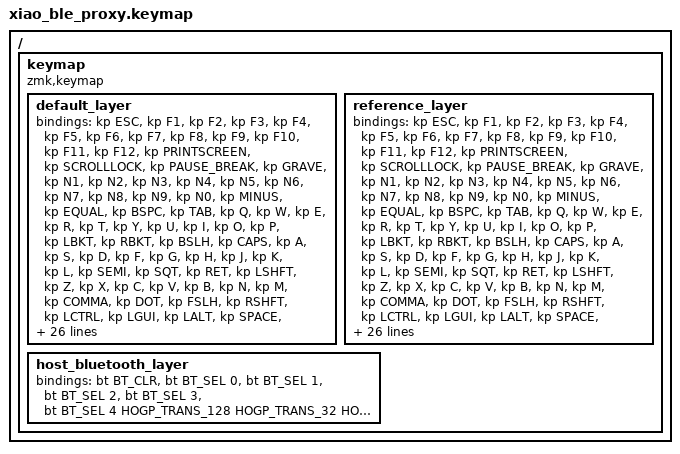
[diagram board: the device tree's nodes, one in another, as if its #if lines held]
#include <behaviors.dtsi>
#include <dt-bindings/zmk/keys.h>
#include <dt-bindings/zmk/bt.h>

#define HOGP_TRANS_2 &trans &trans
#define HOGP_TRANS_4 HOGP_TRANS_2 HOGP_TRANS_2
#define HOGP_TRANS_8 HOGP_TRANS_4 HOGP_TRANS_4
#define HOGP_TRANS_16 HOGP_TRANS_8 HOGP_TRANS_8
#define HOGP_TRANS_32 HOGP_TRANS_16 HOGP_TRANS_16
#define HOGP_TRANS_64 HOGP_TRANS_32 HOGP_TRANS_32
#define HOGP_TRANS_128 HOGP_TRANS_64 HOGP_TRANS_64

/ {
    keymap {
        compatible = "zmk,keymap";

        /* Layer 0: active default mapping */
        default_layer {
            bindings = <
                /* 0..15 */
                &kp ESC   &kp F1    &kp F2    &kp F3    &kp F4    &kp F5    &kp F6    &kp F7
                &kp F8    &kp F9    &kp F10   &kp F11   &kp F12   &kp PRINTSCREEN &kp SCROLLLOCK &kp PAUSE_BREAK

                /* 16..29 */
                &kp GRAVE &kp N1    &kp N2    &kp N3    &kp N4    &kp N5    &kp N6    &kp N7
                &kp N8    &kp N9    &kp N0    &kp MINUS &kp EQUAL &kp BSPC

                /* 30..43 */
                &kp TAB   &kp Q     &kp W     &kp E     &kp R     &kp T     &kp Y     &kp U
                &kp I     &kp O     &kp P     &kp LBKT  &kp RBKT  &kp BSLH

                /* 44..56 */
                &kp CAPS  &kp A     &kp S     &kp D     &kp F     &kp G     &kp H     &kp J
                &kp K     &kp L     &kp SEMI  &kp SQT   &kp RET

                /* 57..68 */
                &kp LSHFT &kp Z     &kp X     &kp C     &kp V     &kp B     &kp N     &kp M
                &kp COMMA &kp DOT   &kp FSLH  &kp RSHFT

                /* 69..76 */
                &kp LCTRL &kp LGUI  &kp LALT  &kp SPACE &kp RALT  &kp RGUI  &mo 2     &kp RCTRL

                /* 77..86 */
                &kp INS   &kp HOME  &kp PG_UP &kp DEL   &kp END   &kp PG_DN &kp UP    &kp LEFT
                &kp DOWN  &kp RIGHT

                /* 87..103 */
                &kp KP_NUM   &kp KP_DIVIDE &kp KP_MULTIPLY &kp KP_MINUS
                &kp KP_N7    &kp KP_N8     &kp KP_N9       &kp KP_PLUS
                &kp KP_N4    &kp KP_N5     &kp KP_N6
                &kp KP_N1    &kp KP_N2     &kp KP_N3       &kp KP_ENTER
                &kp KP_N0    &kp KP_DOT

                /* 104..113: consumer proxy slots from 12-byte report */
                &kp C_VOL_DN &kp C_VOL_UP &kp C_MUTE &kp C_PREV
                &kp C_PP     &kp C_NEXT   &kp C_STOP &kp C_BRI_UP
                &kp C_BRI_DN &kp C_MUTE

                /* 114..117: external tact switches on pins 0..3 */
                &kp A &kp B &kp C &kp D

                /* 118..122: pointer buttons (L/R/M/B4/B5) */
                &none &none &none &none &none

                /* 123..126: pointer move pulses (left/right/up/down) */
                &kp LEFT  &kp RIGHT &kp UP    &kp DOWN

                /* 127..131: wheel/pan pulses and ISO Non-US Backslash */
                &kp PG_UP &kp PG_DN &kp LEFT  &kp RIGHT &kp NUBS

                /* 132..143: JIS/IME keys (host mapping may vary)
                 * International 1..6 followed by Language 1..6.
                 */
                &kp INT_RO   &kp INT_KANA   &kp INT_YEN
                &kp INT_HENKAN &kp INT_MUHENKAN &kp INT_KPJPCOMMA
                &kp LANG1    &kp LANG2      &kp LANG3
                &kp LANG4    &kp LANG5      &kp LANG6

                /* 144..155: extra consumer usages */
                &kp C_AC_BACK    &kp C_AC_FORWARD &kp C_AC_REFRESH &kp C_AC_STOP
                &kp C_AC_HOME    &kp C_AC_SEARCH  &kp C_AC_BOOKMARKS
                &kp C_AL_WWW     &kp C_AL_MAIL    &kp C_AL_CALC
                &kp C_AC_ZOOM_IN &kp C_AC_ZOOM_OUT

                /* 156..167: extended function keys */
                &kp F13 &kp F14 &kp F15 &kp F16 &kp F17 &kp F18
                &kp F19 &kp F20 &kp F21 &kp F22 &kp F23 &kp F24
            >;
        };

        /*
         * Layer 1: reference layer using &kp defaults aligned to usage_order[].
         * Not auto-selected; this is for easier visual editing/copy.
         */
        reference_layer {
            bindings = <
                /* 0..15 */
                &kp ESC   &kp F1    &kp F2    &kp F3    &kp F4    &kp F5    &kp F6    &kp F7
                &kp F8    &kp F9    &kp F10   &kp F11   &kp F12   &kp PRINTSCREEN &kp SCROLLLOCK &kp PAUSE_BREAK

                /* 16..29 */
                &kp GRAVE &kp N1    &kp N2    &kp N3    &kp N4    &kp N5    &kp N6    &kp N7
                &kp N8    &kp N9    &kp N0    &kp MINUS &kp EQUAL &kp BSPC

                /* 30..43 */
                &kp TAB   &kp Q     &kp W     &kp E     &kp R     &kp T     &kp Y     &kp U
                &kp I     &kp O     &kp P     &kp LBKT  &kp RBKT  &kp BSLH

                /* 44..56 */
                &kp CAPS  &kp A     &kp S     &kp D     &kp F     &kp G     &kp H     &kp J
                &kp K     &kp L     &kp SEMI  &kp SQT   &kp RET

                /* 57..68 */
                &kp LSHFT &kp Z     &kp X     &kp C     &kp V     &kp B     &kp N     &kp M
                &kp COMMA &kp DOT   &kp FSLH  &kp RSHFT

                /* 69..76 */
                &kp LCTRL &kp LGUI  &kp LALT  &kp SPACE &kp RALT  &kp RGUI  &none     &kp RCTRL

                /* 77..86 */
                &kp INS   &kp HOME  &kp PG_UP &kp DEL   &kp END   &kp PG_DN &kp UP    &kp LEFT
                &kp DOWN  &kp RIGHT

                /* 87..103 */
                &kp KP_NUM   &kp KP_DIVIDE &kp KP_MULTIPLY &kp KP_MINUS
                &kp KP_N7    &kp KP_N8     &kp KP_N9       &kp KP_PLUS
                &kp KP_N4    &kp KP_N5     &kp KP_N6
                &kp KP_N1    &kp KP_N2     &kp KP_N3       &kp KP_ENTER
                &kp KP_N0    &kp KP_DOT

                /* 104..113 */
                &kp C_VOL_DN &kp C_VOL_UP &kp C_MUTE &kp C_PREV
                &kp C_PP     &kp C_NEXT   &kp C_STOP &kp C_BRI_UP
                &kp C_BRI_DN &kp C_MUTE

                /* 114..117 */
                &kp F13 &kp F14 &kp F15 &kp F16

                /* 118..122 */
                &none &none &none &none &none

                /* 123..126 */
                &kp LEFT  &kp RIGHT &kp UP    &kp DOWN

                /* 127..131 */
                &kp PG_UP &kp PG_DN &kp LEFT  &kp RIGHT &kp NUBS

                /* 132..143: JIS/IME keys */
                &kp INT_RO   &kp INT_KANA   &kp INT_YEN
                &kp INT_HENKAN &kp INT_MUHENKAN &kp INT_KPJPCOMMA
                &kp LANG1    &kp LANG2      &kp LANG3
                &kp LANG4    &kp LANG5      &kp LANG6

                /* 144..155: extra consumer usages */
                &kp C_AC_BACK    &kp C_AC_FORWARD &kp C_AC_REFRESH &kp C_AC_STOP
                &kp C_AC_HOME    &kp C_AC_SEARCH  &kp C_AC_BOOKMARKS
                &kp C_AL_WWW     &kp C_AL_MAIL    &kp C_AL_CALC
                &kp C_AC_ZOOM_IN &kp C_AC_ZOOM_OUT

                /* 156..167: extended function keys */
                &kp F13 &kp F14 &kp F15 &kp F16 &kp F17 &kp F18
                &kp F19 &kp F20 &kp F21 &kp F22 &kp F23 &kp F24
            >;
        };

        /* Hold the Application/Menu position (75) from an input keyboard to
         * enter this layer. Esc clears the selected ZMK host profile; F1..F5
         * select profiles 0..4. These are normal upstream ZMK &bt behaviors
         * and are active in the secure-BLE-output build.
         */
        host_bluetooth_layer {
            bindings = <
#if defined(CONFIG_ZMK_BLE)
                &bt BT_CLR
                &bt BT_SEL 0
                &bt BT_SEL 1
                &bt BT_SEL 2
                &bt BT_SEL 3
                &bt BT_SEL 4
                HOGP_TRANS_128 HOGP_TRANS_32 HOGP_TRANS_2
#else
                HOGP_TRANS_128 HOGP_TRANS_32 HOGP_TRANS_8
#endif
            >;
        };
    };
};
